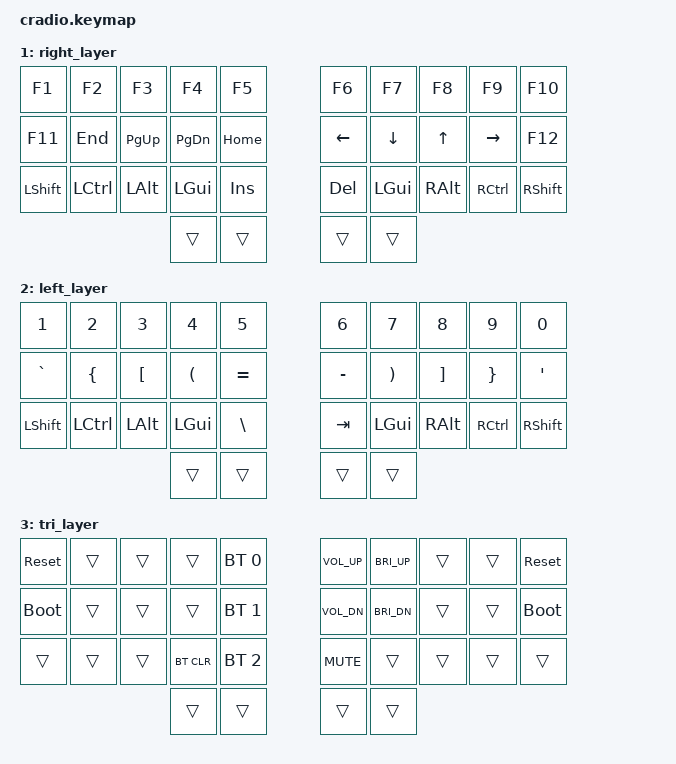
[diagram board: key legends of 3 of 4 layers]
// Copyright (c) 2022 The ZMK Contributors
// SPDX-License-Identifier: MIT

#include <behaviors.dtsi>
#include <dt-bindings/zmk/keys.h>
#include <dt-bindings/zmk/bt.h>

// Home row mods macro
#define HRML(k1,k2,k3,k4) &ht LSHFT k1  &ht LCTRL k2  &ht LALT k3  &ht LGUI k4
#define HRMR(k1,k2,k3,k4) &ht LGUI k1  &ht RALT k2  &ht RCTRL k3  &ht RSHFT k4

/ {
    behaviors {
        ht: hold_tap {
            compatible = "zmk,behavior-hold-tap";
            #binding-cells = <2>;
            flavor = "tap-preferred";
            tapping-term-ms = <220>;
            quick-tap-ms = <150>;
            require-prior-idle-ms = <100>;
            bindings = <&kp>, <&kp>;
        };
        lt: layer_tap {
            compatible = "zmk,behavior-hold-tap";
            #binding-cells = <2>;
            flavor = "balanced";
            tapping-term-ms = <220>;
            quick-tap-ms = <180>;
            require-prior-idle-ms = <100>;
            bindings = <&mo>, <&kp>;
        };
    };

    conditional_layers {
        compatible = "zmk,conditional-layers";
        tri_layer {
            if-layers = <1 2>;
            then-layer = <3>;
        };
    };

    keymap {
        compatible = "zmk,keymap";
        default_layer {
            bindings = <
        //╭──────────┬──────────┬──────────┬──────────┬──────────╮   ╭──────────┬──────────┬──────────┬──────────┬──────────╮
        //│  Q       │  W       │  E       │  R       │  T       │   │  Y       │  U       │  I       │  O       │  P       │
            &kp Q      &kp W      &kp E      &kp R      &kp T          &kp Y      &kp U      &kp I      &kp O      &kp P
        //├──────────┼──────────┼──────────┼──────────┼──────────┤   ├──────────┼──────────┼──────────┼──────────┼──────────┤
        //│  A       │  S       │  D       │  F       │  G       │   │  H       │  J       │  K       │  L       │ ; :      │
            &kp A      &kp S      &kp D      &kp F      &kp G          &kp H      &kp J      &kp K      &kp L      &kp SEMI
        //├──────────┼──────────┼──────────┼──────────┼──────────┤   ├──────────┼──────────┼──────────┼──────────┼──────────┤
        //│  Z       │  X       │  C       │  V       │  B       │   │  N       │  M       │ , <      │ . >      │ / ?      │
            HRML(Z,     X,         C,         V)        &kp B          &kp N      HRMR(M,    COMMA,     DOT,       FSLH)
        //╰──────────┴──────────┴──────────┼──────────┼──────────┤   ├──────────┼──────────┼──────────┴──────────┴──────────╯
                                             &kp ESC   &lt 2 BSPC     &lt 1 SPACE &kp ENTER
        //                                 ╰──────────┴──────────╯   ╰──────────┴──────────╯
            >;
        };

        right_layer {
            bindings = <
        //╭──────────┬──────────┬──────────┬──────────┬──────────╮   ╭──────────┬──────────┬──────────┬──────────┬──────────╮
        //│   F1     │   F2     │    F3    │   F4     │   F5     │   │   F6     │   F7     │    F8    │   F9     │  F10     │
            &kp F1     &kp F2     &kp F3     &kp F4     &kp F5         &kp F6     &kp F7     &kp F8      &kp F9    &kp F10
        //├──────────┼──────────┼──────────┼──────────┼──────────┤   ├──────────┼──────────┼──────────┼──────────┼──────────┤
        //│   F11    │  END     │ PAGE UP  │ PAGE DN  │  HOME    │   │  LEFT    │  DOWN    │   UP     │  RIGHT   │  F12     │
            &kp F11    &kp END    &kp PG_UP  &kp PG_DN  &kp HOME        &kp LEFT   &kp DOWN   &kp UP    &kp RIGHT   &kp F12
        //├──────────┼──────────┼──────────┼──────────┼──────────┤   ├──────────┼──────────┼──────────┼──────────┼──────────┤
        //│  SHIFT   │  CTRL    │  ALT     │  SUPER   │ INSERT   │   │ DELETE   │  SUPER   │  ALT     │   CTRL   │  SHIFT   │
            &kp LSHFT  &kp LCTRL  &kp LALT   &kp LGUI   &kp INS        &kp DEL    &kp LGUI   &kp RALT   &kp RCTRL  &kp RSHFT
        //╰──────────┴──────────┴──────────┼──────────┼──────────┤   ├──────────┼──────────┼──────────┴──────────┴──────────╯
                                             &trans     &trans         &trans     &trans
        //                                 ╰──────────┴──────────╯   ╰──────────┴──────────╯
            >;
        };

        left_layer {
            bindings = <
        //╭──────────┬──────────┬──────────┬──────────┬──────────╮   ╭──────────┬──────────┬──────────┬──────────┬──────────╮
        //│    1     │    2     │    3     │    4     │    5     │   │    6     │    7     │    8     │    9     │    0     │
            &kp N1     &kp N2     &kp N3     &kp N4     &kp N5         &kp N6     &kp N7     &kp N8     &kp N9     &kp N0
        //├──────────┼──────────┼──────────┼──────────┼──────────┤   ├──────────┼──────────┼──────────┼──────────┼──────────┤
        //│   ` ~    │   {      │   [      │   (      │   = +    │   │   - _    │   )      │    ]     │    }     │  ' "     │
            &kp GRAVE  &kp LBRC   &kp LBKT   &kp LPAR   &kp EQUAL      &kp MINUS  &kp RPAR   &kp RBKT   &kp RBRC   &kp SQT
        //├──────────┼──────────┼──────────┼──────────┼──────────┤   ├──────────┼──────────┼──────────┼──────────┼──────────┤
        //│  SHIFT   │  CTRL    │  ALT     │  SUPER   │   \ |    │   │  <TAB>   │  SUPER   │  ALT     │   CTRL   │  SHIFT   │
            &kp LSHFT  &kp LCTRL  &kp LALT   &kp LGUI   &kp BSLH       &kp TAB    &kp LGUI   &kp RALT   &kp RCTRL  &kp RSHFT
        //╰──────────┴──────────┴──────────┼──────────┼──────────┤   ├──────────┼──────────┼──────────┴──────────┴──────────╯
                                             &trans     &trans         &trans     &trans
        //                                 ╰──────────┴──────────╯   ╰──────────┴──────────╯
            >;
        };

        tri_layer {
            bindings = <
        //╭──────────┬──────────┬──────────┬──────────┬──────────╮   ╭──────────┬──────────┬──────────┬──────────┬──────────╮
        //│ RESET    │          │          │          │PROFILE 0 │   │ VOL UP   │ BRITE UP │          │          │  RESET   │
           &sys_reset  &trans     &trans     &trans   &bt BT_SEL 0  &kp C_VOL_UP &kp C_BRI_UP  &trans    &trans   &sys_reset
        //├──────────┼──────────┼──────────┼──────────┼──────────┤   ├──────────┼──────────┼──────────┼──────────┼──────────┤
        //│BOOTLOADER│          │          │          │PROFILE 1 │   │ VOL DN   │ BRITE DN │          │          │BOOTLOADER│
          &bootloader  &trans     &trans     &trans   &bt BT_SEL 1  &kp C_VOL_DN &kp C_BRI_DN  &trans    &trans   &bootloader
        //├──────────┼──────────┼──────────┼──────────┼──────────┤   ├──────────┼──────────┼──────────┼──────────┼──────────┤
        //│          │          │          │ CLEAR BT │PROFILE 2 │   │ VOL MUTE │          │          │          │          │
            &trans     &trans     &trans    &bt BT_CLR &bt BT_SEL 2   &kp C_MUTE   &trans     &trans     &trans     &trans
        //╰──────────┴──────────┴──────────┼──────────┼──────────┤   ├──────────┼──────────┼──────────┴──────────┴──────────╯
                                             &trans     &trans         &trans     &trans
        //                                 ╰──────────┴──────────╯   ╰──────────┴──────────╯
            >;
        };
    };
};
